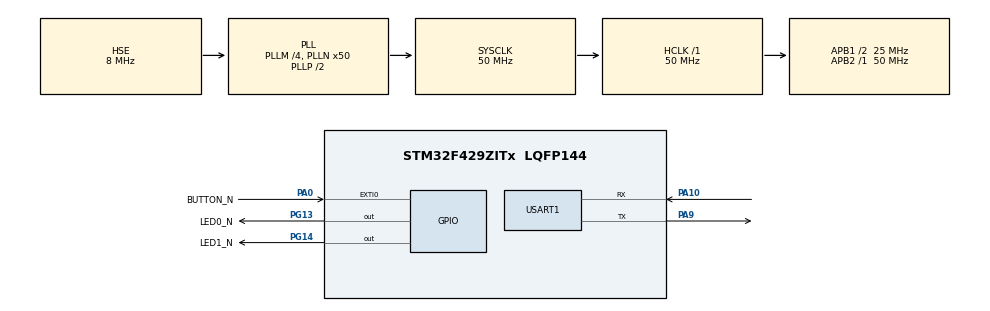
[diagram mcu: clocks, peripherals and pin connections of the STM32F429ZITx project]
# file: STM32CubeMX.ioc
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Mcu.Family=STM32F4
Mcu.Name=STM32F429ZITx
Mcu.Package=LQFP144
NVIC.EXTI0_IRQn=true\:0\:0\:false\:false\:true\:true\:true\:true
NVIC.PriorityGroup=NVIC_PRIORITYGROUP_4
NVIC.TIM8_UP_TIM13_IRQn=true\:15\:0\:false\:false\:true\:false\:true\:true
NVIC.TimeBase=TIM8_UP_TIM13_IRQn
NVIC.TimeBaseIP=TIM8
NVIC.USART1_IRQn=true\:0\:0\:false\:false\:true\:true\:true\:true
PA0/WKUP.GPIO_Label=BUTTON_N
PA0/WKUP.Signal=GPXTI0
PA10.Mode=Asynchronous
PA10.Signal=USART1_RX
PA9.Mode=Asynchronous
PA9.Signal=USART1_TX
PG13.GPIO_Label=LED0_N
PG13.Signal=GPIO_Output
PG14.GPIO_Label=LED1_N
PG14.Signal=GPIO_Output
PH0/OSC_IN.Mode=HSE-External-Oscillator
PH0/OSC_IN.Signal=RCC_OSC_IN
PH1/OSC_OUT.Mode=HSE-External-Oscillator
PH1/OSC_OUT.Signal=RCC_OSC_OUT
ProjectManager.HeapSize=0x200
ProjectManager.StackSize=0x400
ProjectManager.TargetToolchain=MDK-ARM V5
RCC.48MHZClocksFreq_Value=25000000
RCC.AHBFreq_Value=50000000
RCC.APB1CLKDivider=RCC_HCLK_DIV2
RCC.APB1Freq_Value=25000000
RCC.APB1TimFreq_Value=50000000
RCC.APB2Freq_Value=50000000
RCC.APB2TimFreq_Value=50000000
RCC.CortexFreq_Value=50000000
RCC.HCLKFreq_Value=50000000
RCC.HSE_VALUE=8000000
RCC.HSI_VALUE=16000000
RCC.LSE_VALUE=32768
RCC.PLLM=4
RCC.PLLN=50
RCC.PLLSourceVirtual=RCC_PLLSOURCE_HSE
RCC.SYSCLKFreq_VALUE=50000000
RCC.SYSCLKSource=RCC_SYSCLKSOURCE_PLLCLK
RCC.VCOOutputFreq_Value=100000000
USART1.VirtualMode=VM_ASYNC
VP_SYS_VS_tim8.Mode=TIM8
board=custom

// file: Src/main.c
/* USER CODE BEGIN Header */
/**
  ******************************************************************************
  * @file           : main.c
  * @brief          : Main program body
  ******************************************************************************
  * @attention
  *
  * Copyright (c) 2026 STMicroelectronics.
  * All rights reserved.
  *
  * This software is licensed under terms that can be found in the LICENSE file
  * in the root directory of this software component.
  * If no LICENSE file comes with this software, it is provided AS-IS.
  *
  ******************************************************************************
  */
/* USER CODE END Header */
#include "main.h"

/* USER CODE BEGIN Includes */
#include <stdio.h>
#include <cmsis_os2.h>

/* USER CODE END Includes */

UART_HandleTypeDef huart1;

void SystemClock_Config(void);
static void MX_GPIO_Init(void);
static void MX_USART1_UART_Init(void);

/* USER CODE BEGIN 0 */
void app_main(void *argument)
{
 while(1)
 {
  HAL_GPIO_TogglePin(LED1_N_GPIO_Port,LED1_N_Pin);
  osDelay(1000);
 }
}

/* USER CODE END 0 */

int main(void)
{

  /* MCU Configuration--------------------------------------------------------*/

  /* Reset of all peripherals, Initializes the Flash interface and the Systick. */
  HAL_Init();

  /* Configure the system clock */
  SystemClock_Config();

  /* Initialize all configured peripherals */
  MX_GPIO_Init();
  MX_USART1_UART_Init();
  /* USER CODE BEGIN 2 */
	stdio_init();
	printf("Hello Vives\n");
	fflush(stdout);
	//int number;
	//printf("Give number:\n");
	//scanf("%d",&number);
	//printf("incremented number is %d\n",++number);

	osKernelInitialize();         // Initialize CMSIS-RTOS
  osThreadNew(app_main, NULL, NULL);  // Create application main thread
  osKernelStart();           // Start thread execution

  /* USER CODE END 2 */

  /* Infinite loop */
  while (1)
  {

  }
}

void SystemClock_Config(void)
{
  RCC_OscInitTypeDef RCC_OscInitStruct = {0};
  RCC_ClkInitTypeDef RCC_ClkInitStruct = {0};

  /** Configure the main internal regulator output voltage
  */
  __HAL_RCC_PWR_CLK_ENABLE();
  __HAL_PWR_VOLTAGESCALING_CONFIG(PWR_REGULATOR_VOLTAGE_SCALE3);

  /** Initializes the RCC Oscillators according to the specified parameters
  * in the RCC_OscInitTypeDef structure.
  */
  RCC_OscInitStruct.OscillatorType = RCC_OSCILLATORTYPE_HSE;
  RCC_OscInitStruct.HSEState = RCC_HSE_ON;
  RCC_OscInitStruct.PLL.PLLState = RCC_PLL_ON;
  RCC_OscInitStruct.PLL.PLLSource = RCC_PLLSOURCE_HSE;
  RCC_OscInitStruct.PLL.PLLM = 4;
  RCC_OscInitStruct.PLL.PLLN = 50;
  RCC_OscInitStruct.PLL.PLLP = RCC_PLLP_DIV2;
  RCC_OscInitStruct.PLL.PLLQ = 4;
  if (HAL_RCC_OscConfig(&RCC_OscInitStruct) != HAL_OK)
  {
    Error_Handler();
  }

  /** Initializes the CPU, AHB and APB buses clocks
  */
  RCC_ClkInitStruct.ClockType = RCC_CLOCKTYPE_HCLK|RCC_CLOCKTYPE_SYSCLK
                              |RCC_CLOCKTYPE_PCLK1|RCC_CLOCKTYPE_PCLK2;
  RCC_ClkInitStruct.SYSCLKSource = RCC_SYSCLKSOURCE_PLLCLK;
  RCC_ClkInitStruct.AHBCLKDivider = RCC_SYSCLK_DIV1;
  RCC_ClkInitStruct.APB1CLKDivider = RCC_HCLK_DIV2;
  RCC_ClkInitStruct.APB2CLKDivider = RCC_HCLK_DIV1;

  if (HAL_RCC_ClockConfig(&RCC_ClkInitStruct, FLASH_LATENCY_1) != HAL_OK)
  {
    Error_Handler();
  }
}

static void MX_USART1_UART_Init(void)
{

  huart1.Instance = USART1;
  huart1.Init.BaudRate = 115200;
  huart1.Init.WordLength = UART_WORDLENGTH_8B;
  huart1.Init.StopBits = UART_STOPBITS_1;
  huart1.Init.Parity = UART_PARITY_NONE;
  huart1.Init.Mode = UART_MODE_TX_RX;
  huart1.Init.HwFlowCtl = UART_HWCONTROL_NONE;
  huart1.Init.OverSampling = UART_OVERSAMPLING_16;
  if (HAL_UART_Init(&huart1) != HAL_OK)
  {
    Error_Handler();
  }

}

static void MX_GPIO_Init(void)
{
  GPIO_InitTypeDef GPIO_InitStruct = {0};

  /* GPIO Ports Clock Enable */
  __HAL_RCC_GPIOH_CLK_ENABLE();
  __HAL_RCC_GPIOA_CLK_ENABLE();
  __HAL_RCC_GPIOG_CLK_ENABLE();

  /*Configure GPIO pin Output Level */
  HAL_GPIO_WritePin(GPIOG, LED0_N_Pin|LED1_N_Pin, GPIO_PIN_RESET);

  /*Configure GPIO pin : BUTTON_N_Pin */
  GPIO_InitStruct.Pin = BUTTON_N_Pin;
  GPIO_InitStruct.Mode = GPIO_MODE_IT_RISING;
  GPIO_InitStruct.Pull = GPIO_NOPULL;
  HAL_GPIO_Init(BUTTON_N_GPIO_Port, &GPIO_InitStruct);

  /*Configure GPIO pins : LED0_N_Pin LED1_N_Pin */
  GPIO_InitStruct.Pin = LED0_N_Pin|LED1_N_Pin;
  GPIO_InitStruct.Mode = GPIO_MODE_OUTPUT_PP;
  GPIO_InitStruct.Pull = GPIO_NOPULL;
  GPIO_InitStruct.Speed = GPIO_SPEED_FREQ_LOW;
  HAL_GPIO_Init(GPIOG, &GPIO_InitStruct);

  /* EXTI interrupt init*/
  HAL_NVIC_SetPriority(EXTI0_IRQn, 0, 0);
  HAL_NVIC_EnableIRQ(EXTI0_IRQn);

}

/* USER CODE BEGIN 4 */

void HAL_GPIO_EXTI_Callback(uint16_t GPIO_Pin) {

	HAL_GPIO_TogglePin(LED0_N_GPIO_Port,LED0_N_Pin);
}

/* USER CODE END 4 */

void HAL_TIM_PeriodElapsedCallback(TIM_HandleTypeDef *htim)
{
  if (htim->Instance == TIM8)
  {
    HAL_IncTick();
  }
}

void Error_Handler(void)
{
  __disable_irq();
  while (1)
  {
  }
}
